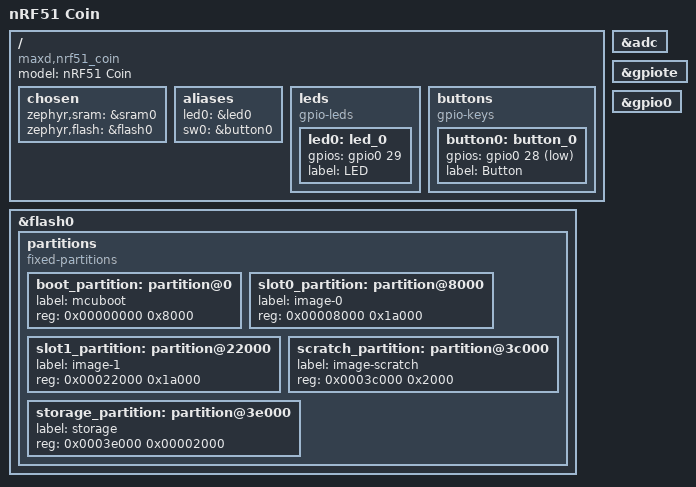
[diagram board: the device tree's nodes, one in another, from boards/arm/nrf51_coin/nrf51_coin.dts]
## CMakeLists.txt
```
cmake_minimum_required(VERSION 3.8.2)

IF(NOT DEFINED ENV{ZEPHYR_BASE})
  set( ENV{ZEPHYR_BASE} "${CMAKE_SOURCE_DIR}/../zephyr" )
ENDIF()
IF(NOT DEFINED ENV{BOARD})
  set( ENV{BOARD} nrf52_coin )
  set( BOARD_ROOT ${CMAKE_SOURCE_DIR} )
ENDIF()
IF(NOT DEFINED ENV{ZEPHYR_TOOLCHAIN_VARIANT})
  set( ENV{ZEPHYR_TOOLCHAIN_VARIANT} zephyr )
ENDIF()
IF(NOT DEFINED ENV{ZEPHYR_SDK_INSTALL_DIR})
  set( ENV{ZEPHYR_SDK_INSTALL_DIR} /opt/zephyr-sdk/ )
ENDIF()

include($ENV{ZEPHYR_BASE}/cmake/app/boilerplate.cmake NO_POLICY_SCOPE)

project(coin)
zephyr_include_directories(
  $ENV{ZEPHYR_BASE}/subsys/bluetooth/host
  ../BLAKE2/ref
)


target_sources(app PRIVATE src/main.c src/bas.c src/io.c src/spaceauth.c ../BLAKE2/ref/blake2s-ref.c)
```

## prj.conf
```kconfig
CONFIG_BT=y
CONFIG_BT_SMP=y
CONFIG_BT_PERIPHERAL=y

CONFIG_BT_PRIVACY=y

CONFIG_BT_SMP_SC_ONLY=y
CONFIG_BT_MAX_CONN=1
CONFIG_BT_MAX_PAIRED=1

CONFIG_BT_SETTINGS=y
CONFIG_BT_BONDABLE=n
CONFIG_BT_DEVICE_NAME="Space"
CONFIG_BT_DEVICE_APPEARANCE=576
CONFIG_BT_ATT_PREPARE_COUNT=5
CONFIG_FLASH=y
CONFIG_FLASH_PAGE_LAYOUT=y
CONFIG_FLASH_MAP=y
CONFIG_FCB=y
CONFIG_SETTINGS=y
CONFIG_SETTINGS_FCB=y

CONFIG_SYS_POWER_MANAGEMENT=y
CONFIG_SYS_POWER_DEEP_SLEEP_STATES=y
CONFIG_DEVICE_POWER_MANAGEMENT=y
CONFIG_ADC=y
CONFIG_ADC_0=y

CONFIG_BT_LL_SW_LEGACY=y

CONFIG_SERIAL=y

CONFIG_PRINTK=y
CONFIG_SHELL=y
CONFIG_LOG=y
CONFIG_KERNEL_SHELL=y
CONFIG_THREAD_MONITOR=y
CONFIG_INIT_STACKS=y
CONFIG_BOOT_BANNER=y
CONFIG_THREAD_NAME=y
CONFIG_DEVICE_SHELL=y
CONFIG_BT_DEBUG_LOG=y

# enable console
CONFIG_CONSOLE=y
CONFIG_UART_CONSOLE=y

CONFIG_ASSERT=y
CONFIG_HW_STACK_PROTECTION=y
```

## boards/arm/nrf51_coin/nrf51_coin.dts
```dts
/*
 * Copyright (c) Maximilian Deubel
 *
 * SPDX-License-Identifier: Apache-2.0
 */

/dts-v1/;
#include <nordic/nrf51822_qfaa.dtsi>

/ {
	model = "nRF51 Coin";
	compatible = "maxd,nrf51_coin", "nordic,nrf51822-qfaa",
		     "nordic,nrf51822";

	chosen {
		zephyr,sram = &sram0;
		zephyr,flash = &flash0;
	};

	aliases {
		led0 = &led0;
		sw0 = &button0;
	};

	leds {
		compatible = "gpio-leds";
		led0: led_0 {
			gpios = <&gpio0 29 0>;
			label = "LED";
		};
	};

	buttons {
		compatible = "gpio-keys";
		button0: button_0 {
			gpios = <&gpio0 28 (GPIO_PUD_PULL_UP |
					    GPIO_INT_ACTIVE_LOW)>;
			label = "Button";
		};
	};
};

&adc {
	status ="okay";
};

&gpiote {
	status ="okay";
};

&gpio0 {
	status ="okay";
};

&flash0 {
	/*
	 * For more information, see:
	 * http://docs.zephyrproject.org/latest/guides/dts/index.html#flash-partitions
	 */
	partitions {
		compatible = "fixed-partitions";
		#address-cells = <1>;
		#size-cells = <1>;

		boot_partition: partition@0 {
			label = "mcuboot";
			reg = <0x00000000 0x8000>;
		};
		slot0_partition: partition@8000 {
			label = "image-0";
			reg = <0x00008000 0x1a000>;
		};
		slot1_partition: partition@22000 {
			label = "image-1";
			reg = <0x00022000 0x1a000>;
		};
		scratch_partition: partition@3c000 {
			label = "image-scratch";
			reg = <0x0003c000 0x2000>;
		};
		storage_partition: partition@3e000 {
			label = "storage";
			reg = <0x0003e000 0x00002000>;
		};
		/*
		 * REMEMBER TO UPDATE ADDRESS AND LENGTH IN prod/gen_bond.py
		 */
	};
};
```

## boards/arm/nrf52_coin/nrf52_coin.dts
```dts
/*
 * Copyright (c) Maximilian Deubel
 *
 * SPDX-License-Identifier: Apache-2.0
 */

/dts-v1/;
#include <nordic/nrf52832_qfaa.dtsi>

/ {
	model = "nRF52 Coin";
	compatible = "maxd,nrf52_coin", "nordic,nrf52832-qfaa",
		     "nordic,nrf52832";

	chosen {
		zephyr,sram = &sram0;
		zephyr,flash = &flash0;
	};

	/* These aliases are provided for compatibility with samples */
	aliases {
		led0 = &led0;
		sw0 = &button0;
	};

	leds {
		compatible = "gpio-leds";
		led0: led_0 {
			gpios = <&gpio0 26 0>;
			label = "LED";
		};
	};

	buttons {
		compatible = "gpio-keys";
		button0: button_0 {
			gpios = <&gpio0 25 (GPIO_PUD_PULL_UP |
					    GPIO_INT_ACTIVE_LOW)>;
			label = "Button";
		};
	};
};

&adc {
	status ="okay";
};

&gpiote {
	status ="okay";
};

&gpio0 {
	status ="okay";
};

&flash0 {
	/*
	 * For more information, see:
	 * http://docs.zephyrproject.org/latest/guides/dts/index.html#flash-partitions
	 */
	partitions {
		compatible = "fixed-partitions";
		#address-cells = <1>;
		#size-cells = <1>;
		slot0_partition: partition@0 {
			label = "image-0";
			reg = <0x00000000 0x32000>;
		};

		storage_partition: partition@32000 {
			label = "storage";
			reg = <0x32000 0x00006000>;
		};
		/*
		 * REMEMBER TO UPDATE ADDRESS AND LENGTH IN prod/gen_bond.py
		 */
	};
};
```

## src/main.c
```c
#include <power.h>

#include <settings/settings.h>

#include <bluetooth/bluetooth.h>
#include <bluetooth/conn.h>
#include <bluetooth/crypto.h>
#include <bluetooth/hci.h>
#include <bluetooth/uuid.h>

#include <logging/log.h>

LOG_MODULE_REGISTER(app);

//our own stuff
#include "bas.h"
#include "spaceauth.h"
#include "io.h"

/**
 * gets called when system enters a new power state
 * is used for turning the LED off before sleep
 * @param state
 */
void sys_pm_notify_power_state_entry(enum power_states state) {
    if (state == SYS_POWER_STATE_DEEP_SLEEP_1) {
        LOG_INF("entering DEEP SLEEP");
        set_blink_intensity(BI_OFF);
    } else {
        LOG_INF("entering state %i", state);
    }
}

struct bt_conn *default_conn = NULL;

static uint8_t batt_adv_bytes[] = {0x0f, 0x18, /* batt level UUID */
                                   0x00}; /* actual batt level */
const static size_t BATT_ADV_BYTES_BLVL_IDX = 2;
// advertising data
static const struct bt_data ad[] = {
        BT_DATA_BYTES(BT_DATA_FLAGS, (BT_LE_AD_GENERAL | BT_LE_AD_NO_BREDR)),
        BT_DATA_BYTES(BT_DATA_UUID16_ALL, 0x00, 0x18, 0x01, 0x18, 0x0f, 0x18),
        BT_DATA(BT_DATA_SVC_DATA16, batt_adv_bytes, sizeof(batt_adv_bytes))
};

static void bt_ready(int err);

static void connected(struct bt_conn *conn, u8_t err);

static void disconnected(struct bt_conn *conn, u8_t reason);

/**
 * gets called when the BLE stack is initialized
 * @param err error while initializing
 */
static void bt_ready(int err) {
    if (err) {
        LOG_ERR("bluetooth init failed (err %d)", err);
        return;
    }

    if (settings_load() != 0) {
        set_blink_intensity(BI_SOS);
        return;
    }

    bt_le_adv_start(BT_LE_ADV_CONN, ad, ARRAY_SIZE(ad), NULL, 0);
    // bt_foreach_bond(BT_ID_DEFAULT,connect_bonded, NULL);
}

/**
 * gets called when connected to the central
 * @param conn connection
 * @param err error connecting
 */
static void connected(struct bt_conn *conn, u8_t err) {
    if (err) {
        LOG_ERR("connection failed (err %u)", err);
        disconnected(NULL, 0);
    } else {
        if (default_conn) {
            bt_conn_unref(default_conn);
            disconnected(NULL, 0);
        }
        default_conn = bt_conn_ref(conn);
        LOG_INF("connected");
        int ret = bt_conn_set_security(conn, BT_SECURITY_L4);
        if (ret) {
            LOG_ERR("Kill connection: insufficient security %i", ret);
            bt_conn_disconnect(conn, BT_HCI_ERR_REMOTE_USER_TERM_CONN);
        } else {
            LOG_INF("bt_conn_security successful");
        }
        set_blink_intensity(BI_AGGRESSIVE);
    }
}

/**
 * gets called when disconnected from central
 * does cleanup and shutdown
 * @note cleanup is probably not needed
 * @param conn
 * @param reason
 */
static void disconnected(struct bt_conn *conn, u8_t reason) {
    ARG_UNUSED(conn);
    LOG_INF("disconnected (reason %u)", reason);

    if (default_conn) {
        bt_conn_unref(default_conn);
        default_conn = NULL;
    }
    LOG_INF("going to sleep");
    sys_pm_force_power_state(SYS_POWER_STATE_DEEP_SLEEP_1);
}

// collection of connection callbacks
static struct bt_conn_cb conn_callbacks = {
        .connected = connected,
        .disconnected = disconnected,
};

static struct k_delayed_work shutdown_timer;

/**
 * shutdown timer callback function
 * @param work
 */
static void shutdown(struct k_work *work) {
    ARG_UNUSED(work);
    if (default_conn) {
        bt_conn_disconnect(default_conn, BT_HCI_ERR_REMOTE_USER_TERM_CONN);
    } else {
        disconnected(NULL, 0);
    }
}

void main(void) {
    // set shutdown timer
    //k_delayed_work_init(&shutdown_timer, shutdown);
    //k_delayed_work_submit(&shutdown_timer, K_SECONDS(10));
    // initialize own parts
    io_init();
    batt_adv_bytes[BATT_ADV_BYTES_BLVL_IDX] = bas_init();
    space_auth_init();

    LOG_INF("turning BLE on");
    // enable the bluetooth stack
    if (bt_enable(bt_ready) != 0) {
        set_blink_intensity(BI_SOS);
        return;
    }
    // set connection and authentication callbacks
    bt_conn_cb_register(&conn_callbacks);
    bt_conn_auth_cb_register(NULL);
}
```

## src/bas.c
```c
#include <zephyr.h>

#include <bluetooth/gatt.h>

#include <device.h>
#include <gpio.h>
#include <adc.h>
#include <hal/nrf_saadc.h>

#include <logging/log.h>

LOG_MODULE_REGISTER(bas);

static u8_t battery = 0U;
static struct device *adc_dev = NULL;

#define ADC_DEVICE_NAME DT_ADC_0_NAME
#define ADC_RESOLUTION 10
#define ADC_GAIN ADC_GAIN_1_3
#define ADC_REFERENCE ADC_REF_INTERNAL
#define ADC_ACQUISITION_TIME ADC_ACQ_TIME_DEFAULT
#define ADC_1ST_CHANNEL_ID 0
#define ADC_1ST_CHANNEL_INPUT NRF_SAADC_INPUT_AIN0

#define BAT_LOW 3
#define BAT_PORT DT_ALIAS_LED0_GPIOS_CONTROLLER

static const struct adc_channel_cfg m_1st_channel_cfg = {
        .gain = ADC_GAIN,
        .reference = ADC_REFERENCE,
        .acquisition_time = ADC_ACQUISITION_TIME,
        .channel_id = ADC_1ST_CHANNEL_ID,
        .input_positive = ADC_1ST_CHANNEL_INPUT,
};

static struct device *init_adc(void) {
    int ret;
    adc_dev = device_get_binding(ADC_DEVICE_NAME);

    if (!adc_dev) {
        LOG_ERR("couldn't get ADC dev binding");
    }

    ret = adc_channel_setup(adc_dev, &m_1st_channel_cfg);
    if (ret != 0) {
        LOG_ERR("adc channel config failed with code %i", ret);
    }

    return adc_dev;
}

static u8_t get_batt_percentage() {
    struct device *dev = device_get_binding(BAT_PORT);
    gpio_pin_configure(dev, BAT_LOW, GPIO_DIR_OUT);
    gpio_pin_write(dev, BAT_LOW, 0);
    nrf_saadc_value_t val = 0;
    if (!adc_dev) {
        LOG_ERR("OH NOES! NO ADC AVAILABLE!");
    } else {
        int ret;
        const struct adc_sequence sequence = {
                .channels = BIT(ADC_1ST_CHANNEL_ID),
                .buffer = &val,
                .buffer_size = sizeof(nrf_saadc_value_t),
                .resolution = ADC_RESOLUTION,
                .oversampling = true,
        };
        ret = adc_read(adc_dev, &sequence);
        if (ret != 0) {
            LOG_ERR("ADC read failed with code %i", ret);
        }
    }
    gpio_pin_configure(dev, BAT_LOW, GPIO_DIR_IN);

    LOG_INF("read ADC val: %i", val);

    float batt_percentage_f = 0.3515625f * (float) val - 200;
    u8_t batt_percentage =
            batt_percentage_f < 0 ? 0 :
            batt_percentage_f > 100 ? 100 :
            (u8_t) batt_percentage_f;
    return batt_percentage;
}

static ssize_t read_blvl(struct bt_conn *conn, const struct bt_gatt_attr *attr,
                         void *buf, u16_t len, u16_t offset) {
    battery = get_batt_percentage();

    const char *value = (const char *) &battery;

    return bt_gatt_attr_read(conn, attr, buf, len, offset, value,
                             sizeof(*value));
}

/* Battery Service Declaration */
BT_GATT_SERVICE_DEFINE(bas_svc,
                       BT_GATT_PRIMARY_SERVICE(BT_UUID_BAS),
                       BT_GATT_CHARACTERISTIC(BT_UUID_BAS_BATTERY_LEVEL,
                                              BT_GATT_CHRC_READ,
                                              BT_GATT_PERM_READ, read_blvl, NULL, &battery),
);

uint8_t bas_init() {
    LOG_INF("initialize battery service");
    init_adc();
    battery = get_batt_percentage();
    return battery;
}
```

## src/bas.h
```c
#ifdef __cplusplus
extern "C" {
#endif

/**
 * Initialize Battery Service.
 * This implementation directly uses the ADC with the on-board resistor divider to measure battery level.
 * @return initially measured battery level
 */
uint8_t bas_init();

#ifdef __cplusplus
}
#endif
```

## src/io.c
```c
#include "io.h"
#include <gpio.h>
#include <power.h>

#include <logging/log.h>

LOG_MODULE_REGISTER(io);

#define LED_PORT DT_ALIAS_LED0_GPIOS_CONTROLLER
#define LED DT_ALIAS_LED0_GPIOS_PIN
#define BTN DT_ALIAS_SW0_GPIOS_PIN

static struct gpio_callback btn_cb = {{0}};

static struct device *dev = NULL;

struct k_timer blink_timer = {{{{0}}}};

static const int aggressive_blink_ms = 125;
static const int quick_blink_ms = 250;
static const int slow_blink_ms = 500;

static const uint16_t sos_sequence[] = {250, 125, 250, 125, 250, 125,
                                        500, 125, 500, 125, 500, 125,
                                        250, 125, 250, 125, 250, 1000,
                                        250, 125, 250, 125, 250, 125,
                                        500, 125, 500, 125, 500, 125,
                                        250, 125, 250, 125, 250, 125};
static int sos_index = -1;

void set_blink_intensity(blink_state_t intensity) {
    switch (intensity) {
        case BI_ON:
            LOG_INF("turn LED on");
            k_timer_stop(&blink_timer);
            gpio_pin_write(dev, LED, 1);
            break;
        case BI_AGGRESSIVE:
            LOG_INF("aggressive LED blink");
            k_timer_start(&blink_timer, K_MSEC(aggressive_blink_ms), K_MSEC(aggressive_blink_ms));
            break;
        case BI_QUICK:
            LOG_INF("quick LED blink");
            k_timer_start(&blink_timer, K_MSEC(quick_blink_ms), K_MSEC(quick_blink_ms));
            break;
        case BI_SLOW:
            LOG_INF("slow LED blink");
            k_timer_start(&blink_timer, K_MSEC(slow_blink_ms), K_MSEC(slow_blink_ms));
            break;
        case BI_SOS:
            LOG_INF("distress signal");
            gpio_pin_write(dev, LED, 1);
            sos_index = 0;
            k_timer_start(&blink_timer, K_MSEC(sos_sequence[0]), 0);
            break;
        default:
        case BI_OFF:
            LOG_INF("turn LED off");
            k_timer_stop(&blink_timer);
            gpio_pin_write(dev, LED, 0);
            break;
    }
}

static int blink_counter = 0;

static void blink_expiry_function(struct k_timer *timer_id) {
    ARG_UNUSED(timer_id);
    if (sos_index > -1) { //SOS mode
        sos_index += 1;
        if (sos_index < ARRAY_SIZE(sos_sequence)) {
            gpio_pin_write(dev, LED, 1 - (sos_index % 2));
            k_timer_start(&blink_timer, K_MSEC(sos_sequence[sos_index]), 0);
        } else {
            gpio_pin_write(dev, LED, 0);
            sys_pm_force_power_state(SYS_POWER_STATE_DEEP_SLEEP_1);
        }
    } else {
        gpio_pin_write(dev, LED, (blink_counter++) % 2);
    }
}

static void button_pressed(struct device *btn_dev, struct gpio_callback *cb, u32_t pins) {
    ARG_UNUSED(btn_dev);
    ARG_UNUSED(cb);
    ARG_UNUSED(pins);
    //LOG_INF("button pressed");
}

void io_init() {
    LOG_INF("initialize LED and button");
    dev = device_get_binding(LED_PORT);

    gpio_pin_configure(dev, LED, GPIO_DIR_OUT);
    gpio_pin_configure(dev, BTN,
                       GPIO_DIR_IN | GPIO_PUD_PULL_UP | GPIO_INT_LEVEL |
                       GPIO_INT | GPIO_INT_ACTIVE_LOW);
    gpio_init_callback(&btn_cb, button_pressed, BIT(BTN));
    gpio_add_callback(dev, &btn_cb);
    gpio_pin_enable_callback(dev, BTN);

    k_timer_init(&blink_timer, blink_expiry_function, NULL);
    set_blink_intensity(BI_ON);
}
```

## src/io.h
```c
#pragma once

#ifdef __cplusplus
extern "C" {
#endif

typedef enum blink_state_t {
    BI_ON = 0,
    BI_AGGRESSIVE,
    BI_QUICK,
    BI_SLOW,
    BI_OFF,
    BI_SOS
} blink_state_t;

/**
 * Initializes the LED and the Button (with an empty callback function just for wakeup).
 * Also sets up a timer for use for the blinking function.
 */
void io_init();

/**
 * Sets the interval of the LED blinking function.
 * @param intensity
 */
void set_blink_intensity(blink_state_t intensity);

#ifdef __cplusplus
}
#endif
```

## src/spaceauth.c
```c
#include <zephyr.h>
#include <settings/settings.h>
#include <bluetooth/gatt.h>

#include "blake2.h"
#include "spaceauth.h"

#include <logging/log.h>

LOG_MODULE_REGISTER(spaceauth);


static struct bt_uuid_128 auth_service_uuid = BT_UUID_INIT_128(
        0xee, 0x8a, 0xcb, 0x07, 0x8d, 0xe1, 0xfc, 0x3b,
        0xfe, 0x8e, 0x69, 0x22, 0x41, 0xbe, 0x87, 0x66);

static struct bt_uuid_128 auth_challenge_uuid = BT_UUID_INIT_128(
        0xd5, 0x12, 0x7b, 0x77, 0xce, 0xba, 0xa7, 0xb1,
        0x86, 0x9a, 0x90, 0x47, 0x02, 0xc9, 0x3d, 0x95);

static struct bt_uuid_128 auth_response_uuid = BT_UUID_INIT_128(
        0x06, 0x3f, 0x0b, 0x51, 0xbf, 0x48, 0x4f, 0x95,
        0x92, 0xd7, 0x28, 0x5c, 0xd6, 0xfd, 0xd2, 0x2f);

static uint8_t auth_key[BLAKE2S_KEYBYTES] = {0};
static uint8_t challenge[BLAKE2S_BLOCKBYTES] = {0};
static uint8_t response[BLAKE2S_OUTBYTES] = {0};

static u16_t ccc_value;

static void ccc_cfg_changed(const struct bt_gatt_attr *attr, u16_t value) {
    ARG_UNUSED(attr);
    ccc_value = value;
}

static void indicate_cb(struct bt_conn *conn, const struct bt_gatt_attr *attr,
                        u8_t err) {
    ARG_UNUSED(attr);
    ARG_UNUSED(conn);
    if (err != 0U) {
        LOG_ERR("indication fail: %i", err);
    } else {
        LOG_INF("indication success");
    }
}

static struct bt_gatt_indicate_params ind_params = {.data=response, .len=BLAKE2S_OUTBYTES, .attr=NULL, .func=&indicate_cb};

static ssize_t write_challenge(struct bt_conn *conn,
                               const struct bt_gatt_attr *attr,
                               const void *buf, u16_t len,
                               u16_t offset, u8_t flags);

static ssize_t read_response(struct bt_conn *conn,
                             const struct bt_gatt_attr *attr,
                             void *buf, u16_t len,
                             u16_t offset) {
    const char *value = attr->user_data;

    return bt_gatt_attr_read(conn, attr, buf, len, offset, value,
                             BLAKE2S_OUTBYTES);
}

BT_GATT_SERVICE_DEFINE(auth_svc,
                       BT_GATT_PRIMARY_SERVICE(&auth_service_uuid),
                       BT_GATT_CHARACTERISTIC(&auth_challenge_uuid.uuid, BT_GATT_CHRC_WRITE | BT_GATT_CHRC_AUTH,
                                              BT_GATT_PERM_WRITE_AUTHEN | BT_GATT_PERM_WRITE_ENCRYPT,
                                              NULL, write_challenge, challenge),
                       BT_GATT_CHARACTERISTIC(&auth_response_uuid.uuid, BT_GATT_CHRC_READ | BT_GATT_CHRC_INDICATE,
                                              BT_GATT_PERM_READ_AUTHEN | BT_GATT_PERM_READ_ENCRYPT,
                                              read_response, NULL, response),
                       BT_GATT_CCC(ccc_cfg_changed, BT_GATT_PERM_READ | BT_GATT_PERM_WRITE),
);

static const size_t INDICATION_PROTOCOL_OVERHEAD = 3;
static const size_t AUTH_RESPONSE_CHR_VALUE_HANDLE = 4;

static ssize_t write_challenge(struct bt_conn *conn,
                               const struct bt_gatt_attr *attr,
                               const void *buf, u16_t len,
                               u16_t offset, u8_t flags) {
    ARG_UNUSED(attr);
    ARG_UNUSED(flags);
    if (offset + len > BLAKE2S_BLOCKBYTES) {
        return BT_GATT_ERR(BT_ATT_ERR_INVALID_OFFSET);
    }

    memcpy(challenge + offset, buf, len);
    LOG_INF("write challenge offset: %i, len: %i", offset, len);

    if (offset + len == BLAKE2S_BLOCKBYTES) {
        blake2s(response, BLAKE2S_OUTBYTES, challenge, BLAKE2S_BLOCKBYTES, auth_key, BLAKE2S_KEYBYTES);
        if (ccc_value == BT_GATT_CCC_INDICATE) {
            ind_params.attr = &auth_svc.attrs[AUTH_RESPONSE_CHR_VALUE_HANDLE];
            u16_t mtu = bt_gatt_get_mtu(conn);
            ind_params.len = MIN(mtu - INDICATION_PROTOCOL_OVERHEAD, BLAKE2S_OUTBYTES);
            LOG_INF("connection has MTU: %u", mtu);
            bt_gatt_indicate(NULL, &ind_params);
        }
    }

    return len;
}

//settings stuff
static int set(const char *key, size_t len_rd,
               settings_read_cb read_cb, void *cb_arg) {
    ARG_UNUSED(len_rd);
    const char *next;

    size_t key_len = (size_t) settings_name_next(key, &next);
    if (!next) {
        if (!strncmp(key, "key", key_len)) {
            ssize_t len = read_cb(cb_arg, auth_key, BLAKE2S_KEYBYTES);
            if (len != BLAKE2S_KEYBYTES) {
                memset(auth_key, 0, BLAKE2S_KEYBYTES);
                return (len < 0) ? len : -EINVAL;
            }
            LOG_INF("loaded spacekey");
            return 0;
        }
    }
    return -ENOENT;
}

static struct settings_handler auth_settings = {
        .name = "space",
        .h_set = set,
};

void space_auth_init(void) {
    LOG_INF("initialize space auth");
    int err;

    err = settings_subsys_init();
    if (err) {
        LOG_ERR("settings_subsys_init failed (err %d)", err);
    }

    err = settings_register(&auth_settings);
    if (err) {
        LOG_ERR("ps_settings_register failed (err %d)", err);
    }
}
```

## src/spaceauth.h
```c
#pragma once

#ifdef __cplusplus
extern "C" {
#endif

/**
 * Initialize Space Authentication Service.
 * This service uses a 32 Byte key which is loaded via the settings API.
 * It uses the key to sign a 64 Byte challenge using blake2s (reference impl) to create a response.
 */
void space_auth_init(void);

#ifdef __cplusplus
}
#endif
```
